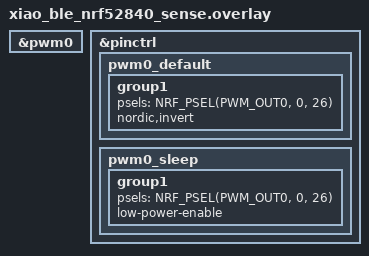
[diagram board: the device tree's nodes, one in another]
&pwm0 {
	status = "okay";
};

&pinctrl {
	pwm0_default: pwm0_default {
		group1 {
			psels = <NRF_PSEL(PWM_OUT0, 0, 26)>;  //Led Vermelho
			nordic,invert;
		};
	};

	pwm0_sleep: pwm0_sleep {
		group1 {
			psels = <NRF_PSEL(PWM_OUT0, 0, 26)>; //Led Vermelho
			low-power-enable;
		};
	};
};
